# earlgrey register map
Vendor: lowRISC; File version: 0.1
CPU: ibex rev01, little endian, no MPU, no FPU, VTOR, 2 interrupt priority bits, 2 interrupts
Registers are 32-bit, read-write, no defined reset value unless marked. A register's access mark holds for its fields unless they carry their own. Offsets are from the block's base; [hi:lo] are bit positions.

## PWRMGR_AON — Sequences on-chip power, clocks, and resets through different reset and power states
Base 0x40400000
0x40 CTRL_CFG_REGWEN ro — Controls the configurability of the !!CONTROL register.This register ensures the contents do not change once a low power hint andWFI has occurred.It unlocks whenever a low power transition has completed (transition back to theACTIVE state) for any reason.
  [0] EN — Configuration enable.This bit defaults to 1 and is set to 0 by hardware when low power entry is initiated.When the device transitions back from low power state to active state, this bit is setback to 1 to allow software configuration of !!CONTROL
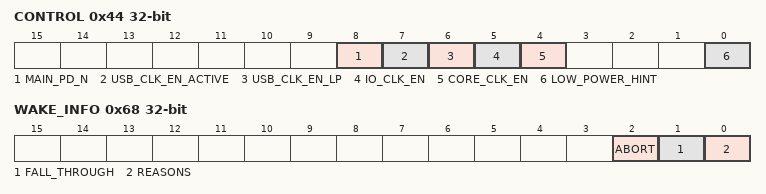
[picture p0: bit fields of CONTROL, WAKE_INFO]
0x44 CONTROL
  [8] MAIN_PD_N — Active low, main power domain power down
  [7] USB_CLK_EN_ACTIVE — USB clock enable during active power state
  [6] USB_CLK_EN_LP — USB clock enable during low power state
  [5] IO_CLK_EN — IO clock enable during low power state
  [4] CORE_CLK_EN — core clock enable during low power state
  [0] LOW_POWER_HINT — The low power hint to power manager.The hint is an indication for how the manager should treat the next WFI.Once the power manager begins a low power transition, or if a valid reset request is registered,this bit is automatically cleared by HW.
0x48 CFG_CDC_SYNC — The configuration registers CONTROL, WAKEUP_EN, RESET_EN are all written in thefast clock domain but used in the slow clock domain.The configuration are not propogated across the clock boundary until thisregister is triggered and read. See fields below for more details
  [0] SYNC — Configuration sync. When this bit is written to 1, a sync pulse is generated. Whenthe sync completes, this bit then self clears.Software should write this bit to 1, wait for it to clear, before assuming the slow clockdomain has assumed the programmed values.
0x4C WAKEUP_EN_REGWEN — Configuration enable for wakeup_en register
  [0] EN — When 1, WAKEUP_EN register can be configured.When 0, WAKEUP_EN register cannot be configured.
0x50 WAKEUP_EN — Bit mask for enabled wakeups
  [0] EN_0 — Whenever a particular bit is set to 1, that wakeup is also enabled.Whenever a particular bit is set to 0, that wakeup cannot wake the device from low power.
0x54 WAKE_STATUS ro — A read only register of all current wake requests post enable mask
  [0] VAL_0 — Current value of wake requests
0x58 RESET_EN_REGWEN — Configuration enable for reset_en register
  [0] EN — When 1, RESET_EN register can be configured.When 0, RESET_EN register cannot be configured.
0x5C RESET_EN — Bit mask for enabled reset requests
  [0] EN_0 — Whenever a particular bit is set to 1, that reset request is enabled.Whenever a particular bit is set to 0, that reset request cannot reset the device.
0x60 RESET_STATUS ro — A read only register of all current reset requests post enable mask
  [0] VAL_0 — Current value of reset request
0x64 WAKE_INFO_CAPTURE_DIS — Disables capture by WAKE_INFO
  [0] VAL — When written to 1, WAKE INFO capture is suppressed.When written to 0, WAKE_INFO capture is controlled by HW.
0x68 WAKE_INFO — Indicates which functions caused the chip to wakeup.This register starts recording upon a valid low power entry with WAKE_INFO_CAPTURE_DIS off.Capture continues until it is explicitly disabled by setting WAKE_INFO_CAPTURE_DIS.This means it is possible to capture multiple wakeup reasons.
  [2] ABORT — The abort wakeup reason indicates that despite setting a WFI and providing a low powerhint, an active flash / lifecycle / otp transaction was ongoing when the power controllerattempted to initiate low power entry.The power manager detects this condition, halts low power entry and reports as a wakeup reason
  [1] FALL_THROUGH — The fall through wakeup reason indicates that despite setting a WFI and providing a low powerhint, an interrupt arrived at just the right time to break the executing core out of WFI.The power manager detects this condition, halts low power entry and reports as a wakeup reason
  [0] REASONS — Various peripheral wake reasons
